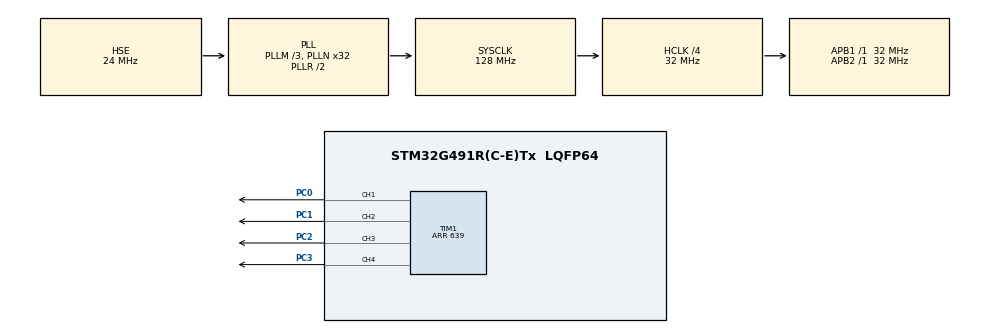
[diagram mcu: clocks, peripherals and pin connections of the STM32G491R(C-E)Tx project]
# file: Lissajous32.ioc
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FREERTOS.MEMORY_ALLOCATION=1
FREERTOS.Tasks01=defaultTask,0,512,sigGenTask,As weak,NULL,Static,defaultTaskBuffer,defaultTaskControlBlock
FREERTOS.configENABLE_FPU=1
FREERTOS.configRECORD_STACK_HIGH_ADDRESS=0
Mcu.Family=STM32G4
Mcu.Name=STM32G491R(C-E)Tx
Mcu.Package=LQFP64
NUCLEO-G491RE.BUTTON=0
NUCLEO-G491RE.LD2=false
NUCLEO-G491RE.VCP=false
NVIC.PriorityGroup=NVIC_PRIORITYGROUP_4
NVIC.TIM1_UP_TIM16_IRQn=true\:5\:0\:false\:false\:true\:true\:true\:true\:true
NVIC.TIM7_IRQn=true\:15\:0\:false\:false\:true\:false\:false\:true\:true
NVIC.TimeBase=TIM7_IRQn
NVIC.TimeBaseIP=TIM7
PA13.GPIO_Label=T_SWDIO
PA13.Mode=Trace_Asynchronous_SW
PA13.Signal=SYS_JTMS-SWDIO
PA14.GPIO_Label=T_SWCLK
PA14.Mode=Trace_Asynchronous_SW
PA14.Signal=SYS_JTCK-SWCLK
PB3.GPIO_Label=T_SWO
PB3.Mode=Trace_Asynchronous_SW
PB3.Signal=SYS_JTDO-SWO
PC0.Signal=S_TIM1_CH1
PC1.Signal=S_TIM1_CH2
PC14-OSC32_IN.GPIO_Label=RCC_OSC32_IN
PC14-OSC32_IN.Mode=LSE-External-Oscillator
PC14-OSC32_IN.Signal=RCC_OSC32_IN
PC15-OSC32_OUT.GPIO_Label=RCC_OSC32_OUT
PC15-OSC32_OUT.Mode=LSE-External-Oscillator
PC15-OSC32_OUT.Signal=RCC_OSC32_OUT
PC2.Signal=S_TIM1_CH3
PC3.Signal=S_TIM1_CH4
PF0-OSC_IN.GPIO_Label=RCC_OSC_IN
PF0-OSC_IN.Mode=HSE-External-Oscillator
PF0-OSC_IN.Signal=RCC_OSC_IN
PF1-OSC_OUT.GPIO_Label=RCC_OSC_OUT
PF1-OSC_OUT.Mode=HSE-External-Oscillator
PF1-OSC_OUT.Signal=RCC_OSC_OUT
ProjectManager.HeapSize=0x200
ProjectManager.StackSize=0x400
ProjectManager.TargetToolchain=STM32CubeIDE
RCC.ADC12Freq_Value=128000000
RCC.ADC345Freq_Value=128000000
RCC.AHBCLKDivider=RCC_SYSCLK_DIV4
RCC.AHBFreq_Value=32000000
RCC.APB1Freq_Value=32000000
RCC.APB1TimFreq_Value=32000000
RCC.APB2Freq_Value=32000000
RCC.APB2TimFreq_Value=32000000
RCC.CortexFreq_Value=32000000
RCC.EXTERNAL_CLOCK_VALUE=12288000
RCC.HCLKFreq_Value=32000000
RCC.HSE_VALUE=24000000
RCC.HSI48_VALUE=48000000
RCC.HSI_VALUE=16000000
RCC.PLLM=RCC_PLLM_DIV3
RCC.PLLN=32
RCC.PLLSourceVirtual=RCC_PLLSOURCE_HSE
RCC.RTCClockSelection=RCC_RTCCLKSOURCE_LSE
RCC.SYSCLKFreq_VALUE=128000000
RCC.SYSCLKSource=RCC_SYSCLKSOURCE_PLLCLK
RCC.USBFreq_Value=48000000
RCC.VCOOutputFreq_Value=256000000
SH.S_TIM1_CH1.0=TIM1_CH1,PWM Generation1 CH1
SH.S_TIM1_CH2.0=TIM1_CH2,PWM Generation2 CH2
SH.S_TIM1_CH3.0=TIM1_CH3,PWM Generation3 CH3
SH.S_TIM1_CH4.0=TIM1_CH4,PWM Generation4 CH4
TIM1.Channel-PWM\ Generation1\ CH1=TIM_CHANNEL_1
TIM1.Channel-PWM\ Generation2\ CH2=TIM_CHANNEL_2
TIM1.Channel-PWM\ Generation3\ CH3=TIM_CHANNEL_3
TIM1.Channel-PWM\ Generation4\ CH4=TIM_CHANNEL_4
TIM1.PeriodNoDither=639
VP_FREERTOS_VS_CMSIS_V1.Mode=CMSIS_V1
VP_SYS_VS_DBSignals.Mode=DisableDeadBatterySignals
VP_SYS_VS_tim7.Mode=TIM7
VP_TIM1_VS_ClockSourceINT.Mode=Internal
board=NUCLEO-G491RE

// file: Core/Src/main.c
/* USER CODE BEGIN Header */
/**
  ******************************************************************************
  * @file           : main.c
  * @brief          : Main program body
  ******************************************************************************
  * @attention
  *
  * Copyright (c) 2025 STMicroelectronics.
  * All rights reserved.
  *
  * This software is licensed under terms that can be found in the LICENSE file
  * in the root directory of this software component.
  * If no LICENSE file comes with this software, it is provided AS-IS.
  *
  ******************************************************************************
  */
/* USER CODE END Header */
#include "main.h"
#include "cmsis_os.h"

/* USER CODE BEGIN Includes */
#include "../../src/pwmdma.h"
#include "../../src/itm_debug.h"
/* USER CODE END Includes */

TIM_HandleTypeDef htim1;

osThreadId defaultTaskHandle;
uint32_t defaultTaskBuffer[ 512 ];
osStaticThreadDef_t defaultTaskControlBlock;

void SystemClock_Config(void);
static void MX_GPIO_Init(void);
static void MX_TIM1_Init(void);
void sigGenTask(void const * argument);

int main(void)
{

  /* MCU Configuration--------------------------------------------------------*/

  /* Reset of all peripherals, Initializes the Flash interface and the Systick. */
  HAL_Init();

  /* Configure the system clock */
  SystemClock_Config();

  /* USER CODE BEGIN SysInit */
  //ITM_SendChar(0x42);

  /* USER CODE END SysInit */

  /* Initialize all configured peripherals */
  MX_GPIO_Init();
  MX_TIM1_Init();

  /* Create the thread(s) */
  /* definition and creation of defaultTask */
  osThreadStaticDef(defaultTask, sigGenTask, osPriorityNormal, 0, 512, defaultTaskBuffer, &defaultTaskControlBlock);
  defaultTaskHandle = osThreadCreate(osThread(defaultTask), NULL);

  /* Start scheduler */
  osKernelStart();

  /* We should never get here as control is now taken by the scheduler */

  /* Infinite loop */
  while (1)
  {

  }
}

void SystemClock_Config(void)
{
  RCC_OscInitTypeDef RCC_OscInitStruct = {0};
  RCC_ClkInitTypeDef RCC_ClkInitStruct = {0};

  /** Configure the main internal regulator output voltage
  */
  HAL_PWREx_ControlVoltageScaling(PWR_REGULATOR_VOLTAGE_SCALE1);

  /** Initializes the RCC Oscillators according to the specified parameters
  * in the RCC_OscInitTypeDef structure.
  */
  RCC_OscInitStruct.OscillatorType = RCC_OSCILLATORTYPE_HSE;
  RCC_OscInitStruct.HSEState = RCC_HSE_ON;
  RCC_OscInitStruct.PLL.PLLState = RCC_PLL_ON;
  RCC_OscInitStruct.PLL.PLLSource = RCC_PLLSOURCE_HSE;
  RCC_OscInitStruct.PLL.PLLM = RCC_PLLM_DIV3;
  RCC_OscInitStruct.PLL.PLLN = 32;
  RCC_OscInitStruct.PLL.PLLP = RCC_PLLP_DIV2;
  RCC_OscInitStruct.PLL.PLLQ = RCC_PLLQ_DIV2;
  RCC_OscInitStruct.PLL.PLLR = RCC_PLLR_DIV2;
  if (HAL_RCC_OscConfig(&RCC_OscInitStruct) != HAL_OK)
  {
    Error_Handler();
  }

  /** Initializes the CPU, AHB and APB buses clocks
  */
  RCC_ClkInitStruct.ClockType = RCC_CLOCKTYPE_HCLK|RCC_CLOCKTYPE_SYSCLK
                              |RCC_CLOCKTYPE_PCLK1|RCC_CLOCKTYPE_PCLK2;
  RCC_ClkInitStruct.SYSCLKSource = RCC_SYSCLKSOURCE_PLLCLK;
  RCC_ClkInitStruct.AHBCLKDivider = RCC_SYSCLK_DIV4;
  RCC_ClkInitStruct.APB1CLKDivider = RCC_HCLK_DIV1;
  RCC_ClkInitStruct.APB2CLKDivider = RCC_HCLK_DIV1;

  if (HAL_RCC_ClockConfig(&RCC_ClkInitStruct, FLASH_LATENCY_1) != HAL_OK)
  {
    Error_Handler();
  }
}

static void MX_TIM1_Init(void)
{

  TIM_ClockConfigTypeDef sClockSourceConfig = {0};
  TIM_MasterConfigTypeDef sMasterConfig = {0};
  TIM_OC_InitTypeDef sConfigOC = {0};
  TIM_BreakDeadTimeConfigTypeDef sBreakDeadTimeConfig = {0};

  /* USER CODE BEGIN TIM1_Init 1 */
	HAL_TIM_Base_Start(&htim1);

  /* USER CODE END TIM1_Init 1 */
  htim1.Instance = TIM1;
  htim1.Init.Prescaler = 0;
  htim1.Init.CounterMode = TIM_COUNTERMODE_UP;
  htim1.Init.Period = 639;
  htim1.Init.ClockDivision = TIM_CLOCKDIVISION_DIV1;
  htim1.Init.RepetitionCounter = 0;
  htim1.Init.AutoReloadPreload = TIM_AUTORELOAD_PRELOAD_DISABLE;
  if (HAL_TIM_Base_Init(&htim1) != HAL_OK)
  {
    Error_Handler();
  }
  sClockSourceConfig.ClockSource = TIM_CLOCKSOURCE_INTERNAL;
  if (HAL_TIM_ConfigClockSource(&htim1, &sClockSourceConfig) != HAL_OK)
  {
    Error_Handler();
  }
  if (HAL_TIM_PWM_Init(&htim1) != HAL_OK)
  {
    Error_Handler();
  }
  sMasterConfig.MasterOutputTrigger = TIM_TRGO_RESET;
  sMasterConfig.MasterOutputTrigger2 = TIM_TRGO2_RESET;
  sMasterConfig.MasterSlaveMode = TIM_MASTERSLAVEMODE_DISABLE;
  if (HAL_TIMEx_MasterConfigSynchronization(&htim1, &sMasterConfig) != HAL_OK)
  {
    Error_Handler();
  }
  sConfigOC.OCMode = TIM_OCMODE_PWM1;
  sConfigOC.Pulse = 0;
  sConfigOC.OCPolarity = TIM_OCPOLARITY_HIGH;
  sConfigOC.OCNPolarity = TIM_OCNPOLARITY_HIGH;
  sConfigOC.OCFastMode = TIM_OCFAST_DISABLE;
  sConfigOC.OCIdleState = TIM_OCIDLESTATE_RESET;
  sConfigOC.OCNIdleState = TIM_OCNIDLESTATE_RESET;
  if (HAL_TIM_PWM_ConfigChannel(&htim1, &sConfigOC, TIM_CHANNEL_1) != HAL_OK)
  {
    Error_Handler();
  }
  if (HAL_TIM_PWM_ConfigChannel(&htim1, &sConfigOC, TIM_CHANNEL_2) != HAL_OK)
  {
    Error_Handler();
  }
  if (HAL_TIM_PWM_ConfigChannel(&htim1, &sConfigOC, TIM_CHANNEL_3) != HAL_OK)
  {
    Error_Handler();
  }
  if (HAL_TIM_PWM_ConfigChannel(&htim1, &sConfigOC, TIM_CHANNEL_4) != HAL_OK)
  {
    Error_Handler();
  }
  sBreakDeadTimeConfig.OffStateRunMode = TIM_OSSR_DISABLE;
  sBreakDeadTimeConfig.OffStateIDLEMode = TIM_OSSI_DISABLE;
  sBreakDeadTimeConfig.LockLevel = TIM_LOCKLEVEL_OFF;
  sBreakDeadTimeConfig.DeadTime = 0;
  sBreakDeadTimeConfig.BreakState = TIM_BREAK_DISABLE;
  sBreakDeadTimeConfig.BreakPolarity = TIM_BREAKPOLARITY_HIGH;
  sBreakDeadTimeConfig.BreakFilter = 0;
  sBreakDeadTimeConfig.BreakAFMode = TIM_BREAK_AFMODE_INPUT;
  sBreakDeadTimeConfig.Break2State = TIM_BREAK2_DISABLE;
  sBreakDeadTimeConfig.Break2Polarity = TIM_BREAK2POLARITY_HIGH;
  sBreakDeadTimeConfig.Break2Filter = 0;
  sBreakDeadTimeConfig.Break2AFMode = TIM_BREAK_AFMODE_INPUT;
  sBreakDeadTimeConfig.AutomaticOutput = TIM_AUTOMATICOUTPUT_DISABLE;
  if (HAL_TIMEx_ConfigBreakDeadTime(&htim1, &sBreakDeadTimeConfig) != HAL_OK)
  {
    Error_Handler();
  }
  HAL_TIM_MspPostInit(&htim1);

}

static void MX_GPIO_Init(void)
{

  /* GPIO Ports Clock Enable */
  __HAL_RCC_GPIOC_CLK_ENABLE();
  __HAL_RCC_GPIOF_CLK_ENABLE();
  __HAL_RCC_GPIOA_CLK_ENABLE();
  __HAL_RCC_GPIOB_CLK_ENABLE();

}

__weak void sigGenTask(void const * argument)
{
  for(;;)
  {
    osDelay(1);
  }
}

void HAL_TIM_PeriodElapsedCallback(TIM_HandleTypeDef *htim)
{
  if (htim->Instance == TIM7) {
    HAL_IncTick();
  }
  /* USER CODE BEGIN Callback 1 */
  if (htim->Instance == TIM1) {
	  pwm_tim_it();
   }
  /* USER CODE END Callback 1 */
}

void Error_Handler(void)
{
  __disable_irq();
  while (1)
  {
  }
}

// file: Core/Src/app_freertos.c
/* USER CODE BEGIN Header */
/**
  ******************************************************************************
  * File Name          : app_freertos.c
  * Description        : Code for freertos applications
  ******************************************************************************
  * @attention
  *
  * Copyright (c) 2025 STMicroelectronics.
  * All rights reserved.
  *
  * This software is licensed under terms that can be found in the LICENSE file
  * in the root directory of this software component.
  * If no LICENSE file comes with this software, it is provided AS-IS.
  *
  ******************************************************************************
  */
/* USER CODE END Header */

#include "FreeRTOS.h"
#include "task.h"
#include "main.h"

/* GetIdleTaskMemory prototype (linked to static allocation support) */
void vApplicationGetIdleTaskMemory( StaticTask_t **ppxIdleTaskTCBBuffer, StackType_t **ppxIdleTaskStackBuffer, uint32_t *pulIdleTaskStackSize );

/* USER CODE BEGIN GET_IDLE_TASK_MEMORY */
static StaticTask_t xIdleTaskTCBBuffer;
static StackType_t xIdleStack[configMINIMAL_STACK_SIZE];

void vApplicationGetIdleTaskMemory( StaticTask_t **ppxIdleTaskTCBBuffer, StackType_t **ppxIdleTaskStackBuffer, uint32_t *pulIdleTaskStackSize )
{
  *ppxIdleTaskTCBBuffer = &xIdleTaskTCBBuffer;
  *ppxIdleTaskStackBuffer = &xIdleStack[0];
  *pulIdleTaskStackSize = configMINIMAL_STACK_SIZE;
  /* place for user code */
}
/* USER CODE END GET_IDLE_TASK_MEMORY */
